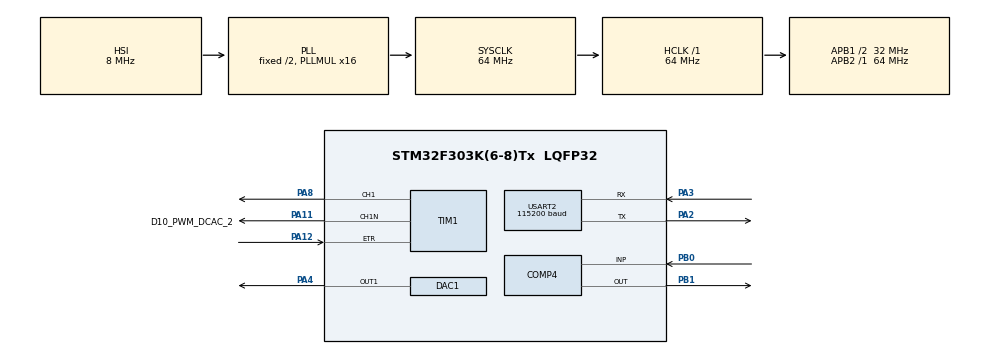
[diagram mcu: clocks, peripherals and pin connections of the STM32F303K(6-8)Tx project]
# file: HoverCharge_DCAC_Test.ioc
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COMP4.InvertingInput=COMP_INVERTINGINPUT_DAC1_CH1
COMP4.OutputPol=COMP_OUTPUTPOL_NONINVERTED
Mcu.Family=STM32F3
Mcu.Name=STM32F303K(6-8)Tx
Mcu.Package=LQFP32
NVIC.PriorityGroup=NVIC_PRIORITYGROUP_4
PA11.GPIO_Label=D10_PWM_DCAC_2
PA11.Mode=PWM Generation1 CH1 CH1N
PA11.Signal=TIM1_CH1N
PA12.Signal=S_TIM1_ETR
PA2.Mode=Asynchronous
PA2.Signal=USART2_TX
PA3.Mode=Asynchronous
PA3.Signal=USART2_RX
PA4.Signal=COMP_DAC11_group
PA8.Signal=S_TIM1_CH1
PB0.Mode=INP
PB0.Signal=COMP4_INP
PB1.Mode=ExternalOutput
PB1.Signal=COMP4_OUT
ProjectManager.HeapSize=0x200
ProjectManager.StackSize=0x400
ProjectManager.TargetToolchain=STM32CubeIDE
RCC.AHBFreq_Value=64000000
RCC.APB1CLKDivider=RCC_HCLK_DIV2
RCC.APB1Freq_Value=32000000
RCC.APB1TimFreq_Value=64000000
RCC.APB2Freq_Value=64000000
RCC.APB2TimFreq_Value=64000000
RCC.CortexFreq_Value=64000000
RCC.HCLKFreq_Value=64000000
RCC.HSE_VALUE=8000000
RCC.HSI_VALUE=8000000
RCC.PLLMUL=RCC_PLL_MUL16
RCC.SYSCLKFreq_VALUE=64000000
RCC.SYSCLKSourceVirtual=RCC_SYSCLKSOURCE_PLLCLK
SH.COMP_DAC11_group.0=DAC1_OUT1,DAC_OUT1
SH.S_TIM1_CH1.0=TIM1_CH1,PWM Generation1 CH1 CH1N
SH.S_TIM1_ETR.0=TIM1_ETR,ClockSourceETR_Mode2
TIM1.Channel-PWM\ Generation1\ CH1\ CH1N=TIM_CHANNEL_1
TIM1.ClockFilter=15
TIM1.DeadTime=50
TIM1.RepetitionCounter=1
TIM1.TIM_MasterOutputTrigger=TIM_TRGO_UPDATE
USART2.BaudRate=115200
USART2.VirtualMode-Asynchronous=VM_ASYNC
VP_COMP4_VS_DAC1OUT1.Mode=INM_DAC1OUT1
board=custom

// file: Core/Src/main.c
/* USER CODE BEGIN Header */
/**
  ******************************************************************************
  * @file           : main.c
  * @brief          : Main program body
  ******************************************************************************
  * @attention
  *
  * Copyright (c) 2024 STMicroelectronics.
  * All rights reserved.
  *
  * This software is licensed under terms that can be found in the LICENSE file
  * in the root directory of this software component.
  * If no LICENSE file comes with this software, it is provided AS-IS.
  *
  ******************************************************************************
  */
/* USER CODE END Header */
#include "main.h"

COMP_HandleTypeDef hcomp4;

DAC_HandleTypeDef hdac1;

TIM_HandleTypeDef htim1;

UART_HandleTypeDef huart2;

/* USER CODE BEGIN PV */
uint32_t PWM_Freq = 100000;
float PWM_DutyC = 50;
int32_t PWM_Period;
int32_t PWM_PulseWidth;

/* USER CODE END PV */

void SystemClock_Config(void);
static void MX_GPIO_Init(void);
static void MX_TIM1_Init(void);
static void MX_USART2_UART_Init(void);
static void MX_COMP4_Init(void);
static void MX_DAC1_Init(void);

int main(void)
{

  /* MCU Configuration--------------------------------------------------------*/

  /* Reset of all peripherals, Initializes the Flash interface and the Systick. */
  HAL_Init();

  /* Configure the system clock */
  SystemClock_Config();

  /* Initialize all configured peripherals */
  MX_GPIO_Init();
  MX_TIM1_Init();
  MX_USART2_UART_Init();
  MX_COMP4_Init();
  MX_DAC1_Init();
  /* USER CODE BEGIN 2 */
    PWM_Period = 1;
    PWM_PulseWidth = 1;

    __HAL_TIM_SET_AUTORELOAD(&htim1, PWM_Period);					//Timer 1 config

    __HAL_TIM_SET_COMPARE(&htim1, TIM_CHANNEL_1, PWM_PulseWidth);	//Tim1 Channel 1 config
    HAL_TIM_PWM_Start(&htim1, TIM_CHANNEL_1);
    HAL_TIMEx_PWMN_Start(&htim1, TIM_CHANNEL_1);

    HAL_DAC_Start(&hdac1, DAC_CHANNEL_1 );

    HAL_COMP_Start(&hcomp4);

  /* USER CODE END 2 */

  /* Infinite loop */
  /* USER CODE BEGIN WHILE */
  while (1)
  {

	  HAL_DAC_SetValue(&hdac1, DAC_CHANNEL_1, DAC_ALIGN_8B_R, 100);
    /* USER CODE END WHILE */

  }
}

void SystemClock_Config(void)
{
  RCC_OscInitTypeDef RCC_OscInitStruct = {0};
  RCC_ClkInitTypeDef RCC_ClkInitStruct = {0};
  RCC_PeriphCLKInitTypeDef PeriphClkInit = {0};

  /** Initializes the RCC Oscillators according to the specified parameters
  * in the RCC_OscInitTypeDef structure.
  */
  RCC_OscInitStruct.OscillatorType = RCC_OSCILLATORTYPE_HSI;
  RCC_OscInitStruct.HSIState = RCC_HSI_ON;
  RCC_OscInitStruct.HSICalibrationValue = RCC_HSICALIBRATION_DEFAULT;
  RCC_OscInitStruct.PLL.PLLState = RCC_PLL_ON;
  RCC_OscInitStruct.PLL.PLLSource = RCC_PLLSOURCE_HSI;
  RCC_OscInitStruct.PLL.PLLMUL = RCC_PLL_MUL16;
  if (HAL_RCC_OscConfig(&RCC_OscInitStruct) != HAL_OK)
  {
    Error_Handler();
  }

  /** Initializes the CPU, AHB and APB buses clocks
  */
  RCC_ClkInitStruct.ClockType = RCC_CLOCKTYPE_HCLK|RCC_CLOCKTYPE_SYSCLK
                              |RCC_CLOCKTYPE_PCLK1|RCC_CLOCKTYPE_PCLK2;
  RCC_ClkInitStruct.SYSCLKSource = RCC_SYSCLKSOURCE_PLLCLK;
  RCC_ClkInitStruct.AHBCLKDivider = RCC_SYSCLK_DIV1;
  RCC_ClkInitStruct.APB1CLKDivider = RCC_HCLK_DIV2;
  RCC_ClkInitStruct.APB2CLKDivider = RCC_HCLK_DIV1;

  if (HAL_RCC_ClockConfig(&RCC_ClkInitStruct, FLASH_LATENCY_2) != HAL_OK)
  {
    Error_Handler();
  }
  PeriphClkInit.PeriphClockSelection = RCC_PERIPHCLK_TIM1;
  PeriphClkInit.Tim1ClockSelection = RCC_TIM1CLK_HCLK;
  if (HAL_RCCEx_PeriphCLKConfig(&PeriphClkInit) != HAL_OK)
  {
    Error_Handler();
  }
}

static void MX_COMP4_Init(void)
{

  hcomp4.Instance = COMP4;
  hcomp4.Init.InvertingInput = COMP_INVERTINGINPUT_DAC1_CH1;
  hcomp4.Init.NonInvertingInput = COMP_NONINVERTINGINPUT_IO1;
  hcomp4.Init.Output = COMP_OUTPUT_NONE;
  hcomp4.Init.OutputPol = COMP_OUTPUTPOL_NONINVERTED;
  hcomp4.Init.BlankingSrce = COMP_BLANKINGSRCE_NONE;
  hcomp4.Init.TriggerMode = COMP_TRIGGERMODE_NONE;
  if (HAL_COMP_Init(&hcomp4) != HAL_OK)
  {
    Error_Handler();
  }

}

static void MX_DAC1_Init(void)
{

  DAC_ChannelConfTypeDef sConfig = {0};

  /** DAC Initialization
  */
  hdac1.Instance = DAC1;
  if (HAL_DAC_Init(&hdac1) != HAL_OK)
  {
    Error_Handler();
  }

  /** DAC channel OUT1 config
  */
  sConfig.DAC_Trigger = DAC_TRIGGER_NONE;
  sConfig.DAC_OutputBuffer = DAC_OUTPUTBUFFER_ENABLE;
  if (HAL_DAC_ConfigChannel(&hdac1, &sConfig, DAC_CHANNEL_1) != HAL_OK)
  {
    Error_Handler();
  }

}

static void MX_TIM1_Init(void)
{

  TIM_ClockConfigTypeDef sClockSourceConfig = {0};
  TIM_MasterConfigTypeDef sMasterConfig = {0};
  TIM_OC_InitTypeDef sConfigOC = {0};
  TIM_BreakDeadTimeConfigTypeDef sBreakDeadTimeConfig = {0};

  htim1.Instance = TIM1;
  htim1.Init.Prescaler = 0;
  htim1.Init.CounterMode = TIM_COUNTERMODE_UP;
  htim1.Init.Period = 65535;
  htim1.Init.ClockDivision = TIM_CLOCKDIVISION_DIV1;
  htim1.Init.RepetitionCounter = 1;
  htim1.Init.AutoReloadPreload = TIM_AUTORELOAD_PRELOAD_DISABLE;
  if (HAL_TIM_Base_Init(&htim1) != HAL_OK)
  {
    Error_Handler();
  }
  sClockSourceConfig.ClockSource = TIM_CLOCKSOURCE_ETRMODE2;
  sClockSourceConfig.ClockPolarity = TIM_CLOCKPOLARITY_NONINVERTED;
  sClockSourceConfig.ClockPrescaler = TIM_CLOCKPRESCALER_DIV1;
  sClockSourceConfig.ClockFilter = 15;
  if (HAL_TIM_ConfigClockSource(&htim1, &sClockSourceConfig) != HAL_OK)
  {
    Error_Handler();
  }
  if (HAL_TIM_PWM_Init(&htim1) != HAL_OK)
  {
    Error_Handler();
  }
  sMasterConfig.MasterOutputTrigger = TIM_TRGO_UPDATE;
  sMasterConfig.MasterOutputTrigger2 = TIM_TRGO2_RESET;
  sMasterConfig.MasterSlaveMode = TIM_MASTERSLAVEMODE_DISABLE;
  if (HAL_TIMEx_MasterConfigSynchronization(&htim1, &sMasterConfig) != HAL_OK)
  {
    Error_Handler();
  }
  sConfigOC.OCMode = TIM_OCMODE_PWM1;
  sConfigOC.Pulse = 0;
  sConfigOC.OCPolarity = TIM_OCPOLARITY_HIGH;
  sConfigOC.OCNPolarity = TIM_OCNPOLARITY_HIGH;
  sConfigOC.OCFastMode = TIM_OCFAST_DISABLE;
  sConfigOC.OCIdleState = TIM_OCIDLESTATE_RESET;
  sConfigOC.OCNIdleState = TIM_OCNIDLESTATE_RESET;
  if (HAL_TIM_PWM_ConfigChannel(&htim1, &sConfigOC, TIM_CHANNEL_1) != HAL_OK)
  {
    Error_Handler();
  }
  sBreakDeadTimeConfig.OffStateRunMode = TIM_OSSR_DISABLE;
  sBreakDeadTimeConfig.OffStateIDLEMode = TIM_OSSI_DISABLE;
  sBreakDeadTimeConfig.LockLevel = TIM_LOCKLEVEL_OFF;
  sBreakDeadTimeConfig.DeadTime = 50;
  sBreakDeadTimeConfig.BreakState = TIM_BREAK_DISABLE;
  sBreakDeadTimeConfig.BreakPolarity = TIM_BREAKPOLARITY_HIGH;
  sBreakDeadTimeConfig.BreakFilter = 0;
  sBreakDeadTimeConfig.Break2State = TIM_BREAK2_DISABLE;
  sBreakDeadTimeConfig.Break2Polarity = TIM_BREAK2POLARITY_HIGH;
  sBreakDeadTimeConfig.Break2Filter = 0;
  sBreakDeadTimeConfig.AutomaticOutput = TIM_AUTOMATICOUTPUT_DISABLE;
  if (HAL_TIMEx_ConfigBreakDeadTime(&htim1, &sBreakDeadTimeConfig) != HAL_OK)
  {
    Error_Handler();
  }
  HAL_TIM_MspPostInit(&htim1);

}

static void MX_USART2_UART_Init(void)
{

  huart2.Instance = USART2;
  huart2.Init.BaudRate = 115200;
  huart2.Init.WordLength = UART_WORDLENGTH_8B;
  huart2.Init.StopBits = UART_STOPBITS_1;
  huart2.Init.Parity = UART_PARITY_NONE;
  huart2.Init.Mode = UART_MODE_TX_RX;
  huart2.Init.HwFlowCtl = UART_HWCONTROL_NONE;
  huart2.Init.OverSampling = UART_OVERSAMPLING_16;
  huart2.Init.OneBitSampling = UART_ONE_BIT_SAMPLE_DISABLE;
  huart2.AdvancedInit.AdvFeatureInit = UART_ADVFEATURE_NO_INIT;
  if (HAL_UART_Init(&huart2) != HAL_OK)
  {
    Error_Handler();
  }

}

static void MX_GPIO_Init(void)
{

  /* GPIO Ports Clock Enable */
  __HAL_RCC_GPIOA_CLK_ENABLE();
  __HAL_RCC_GPIOB_CLK_ENABLE();

}

void Error_Handler(void)
{
  __disable_irq();
  while (1)
  {
  }
}
